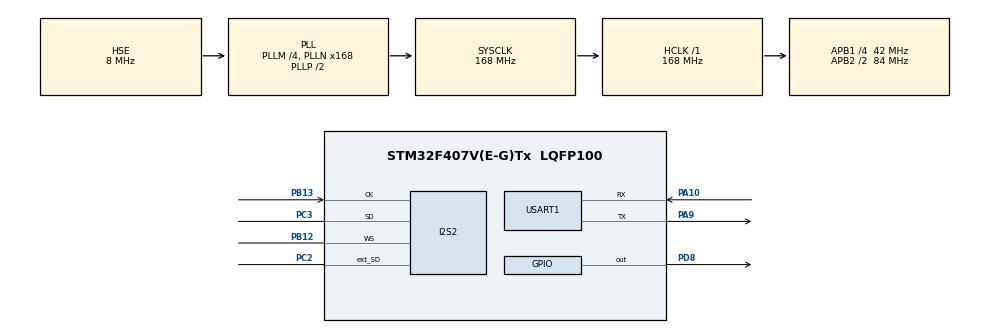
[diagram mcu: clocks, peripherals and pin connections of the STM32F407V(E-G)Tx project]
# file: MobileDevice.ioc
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Dma.I2S2_EXT_RX.0.Direction=DMA_PERIPH_TO_MEMORY
Dma.I2S2_EXT_RX.0.FIFOMode=DMA_FIFOMODE_DISABLE
Dma.I2S2_EXT_RX.0.Instance=DMA1_Stream3
Dma.I2S2_EXT_RX.0.MemDataAlignment=DMA_MDATAALIGN_HALFWORD
Dma.I2S2_EXT_RX.0.MemInc=DMA_MINC_ENABLE
Dma.I2S2_EXT_RX.0.Mode=DMA_CIRCULAR
Dma.I2S2_EXT_RX.0.PeriphDataAlignment=DMA_PDATAALIGN_HALFWORD
Dma.I2S2_EXT_RX.0.PeriphInc=DMA_PINC_DISABLE
Dma.I2S2_EXT_RX.0.Priority=DMA_PRIORITY_LOW
Dma.Request0=I2S2_EXT_RX
Dma.Request1=SPI2_TX
Dma.SPI2_TX.1.Direction=DMA_MEMORY_TO_PERIPH
Dma.SPI2_TX.1.FIFOMode=DMA_FIFOMODE_DISABLE
Dma.SPI2_TX.1.Instance=DMA1_Stream4
Dma.SPI2_TX.1.MemDataAlignment=DMA_MDATAALIGN_HALFWORD
Dma.SPI2_TX.1.MemInc=DMA_MINC_ENABLE
Dma.SPI2_TX.1.Mode=DMA_CIRCULAR
Dma.SPI2_TX.1.PeriphDataAlignment=DMA_PDATAALIGN_HALFWORD
Dma.SPI2_TX.1.PeriphInc=DMA_PINC_DISABLE
Dma.SPI2_TX.1.Priority=DMA_PRIORITY_LOW
I2S2.DataFormat=I2S_DATAFORMAT_16B_EXTENDED
I2S2.ErrorAudioFreq=-0.36 %
I2S2.FullDuplexMode=I2S_FULLDUPLEXMODE_ENABLE
I2S2.Instance=SPI$Index
I2S2.RealAudioFreq=7.971 KHz
I2S2.Standard=I2S_STANDARD_PCM_SHORT
I2S2.VirtualMode=I2S_MODE_SLAVE
Mcu.Family=STM32F4
Mcu.Name=STM32F407V(E-G)Tx
Mcu.Package=LQFP100
NVIC.DMA1_Stream3_IRQn=true\:0\:0\:false\:false\:true\:false
NVIC.DMA1_Stream4_IRQn=true\:0\:0\:false\:false\:true\:false
NVIC.PriorityGroup=NVIC_PRIORITYGROUP_4
NVIC.SPI2_IRQn=true\:0\:0\:false\:false\:true\:true
NVIC.USART1_IRQn=true\:0\:0\:false\:false\:true\:true
PA10.Mode=Asynchronous
PA10.Signal=USART1_RX
PA13.Mode=Serial_Wire
PA13.Signal=SYS_JTMS-SWDIO
PA14.Mode=Serial_Wire
PA14.Signal=SYS_JTCK-SWCLK
PA9.Mode=Asynchronous
PA9.Signal=USART1_TX
PB12.Mode=Full_Duplex_Slave
PB12.Signal=I2S2_WS
PB13.Mode=Full_Duplex_Slave
PB13.Signal=I2S2_CK
PC2.Mode=Full_Duplex_Slave
PC2.Signal=I2S2_ext_SD
PC3.Mode=Full_Duplex_Slave
PC3.Signal=I2S2_SD
PD8.Signal=GPIO_Output
PH0-OSC_IN.Mode=HSE-External-Oscillator
PH0-OSC_IN.Signal=RCC_OSC_IN
PH1-OSC_OUT.Mode=HSE-External-Oscillator
PH1-OSC_OUT.Signal=RCC_OSC_OUT
ProjectManager.HeapSize=0x200
ProjectManager.StackSize=0x400
ProjectManager.TargetToolchain=Other Toolchains (GPDSC)
RCC.48MHZClocksFreq_Value=84000000
RCC.AHBFreq_Value=168000000
RCC.APB1CLKDivider=RCC_HCLK_DIV4
RCC.APB1Freq_Value=42000000
RCC.APB1TimFreq_Value=84000000
RCC.APB2CLKDivider=RCC_HCLK_DIV2
RCC.APB2Freq_Value=84000000
RCC.APB2TimFreq_Value=168000000
RCC.CortexFreq_Value=168000000
RCC.HCLKFreq_Value=168000000
RCC.HSE_VALUE=8000000
RCC.HSI_VALUE=16000000
RCC.LSE_VALUE=32768
RCC.PLLI2SN=50
RCC.PLLM=4
RCC.PLLN=168
RCC.PLLSourceVirtual=RCC_PLLSOURCE_HSE
RCC.SYSCLKFreq_VALUE=168000000
RCC.SYSCLKSource=RCC_SYSCLKSOURCE_PLLCLK
RCC.VCOOutputFreq_Value=336000000
USART1.VirtualMode=VM_ASYNC
board=MobileDevice

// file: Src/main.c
/**
  ******************************************************************************
  * @file           : main.c
  * @brief          : Main program body
  ******************************************************************************
  ** This notice applies to any and all portions of this file
  * that are not between comment pairs USER CODE BEGIN and
  * USER CODE END. Other portions of this file, whether
  * inserted by the user or by software development tools
  * are owned by their respective copyright owners.
  *
  * COPYRIGHT(c) 2018 STMicroelectronics
  *
  * Redistribution and use in source and binary forms, with or without modification,
  * are permitted provided that the following conditions are met:
  *   1. Redistributions of source code must retain the above copyright notice,
  *      this list of conditions and the following disclaimer.
  *   2. Redistributions in binary form must reproduce the above copyright notice,
  *      this list of conditions and the following disclaimer in the documentation
  *      and/or other materials provided with the distribution.
  *   3. Neither the name of STMicroelectronics nor the names of its contributors
  *      may be used to endorse or promote products derived from this software
  *      without specific prior written permission.
  *
  * THIS SOFTWARE IS PROVIDED BY THE COPYRIGHT HOLDERS AND CONTRIBUTORS "AS IS"
  * AND ANY EXPRESS OR IMPLIED WARRANTIES, INCLUDING, BUT NOT LIMITED TO, THE
  * IMPLIED WARRANTIES OF MERCHANTABILITY AND FITNESS FOR A PARTICULAR PURPOSE ARE
  * DISCLAIMED. IN NO EVENT SHALL THE COPYRIGHT HOLDER OR CONTRIBUTORS BE LIABLE
  * FOR ANY DIRECT, INDIRECT, INCIDENTAL, SPECIAL, EXEMPLARY, OR CONSEQUENTIAL
  * DAMAGES (INCLUDING, BUT NOT LIMITED TO, PROCUREMENT OF SUBSTITUTE GOODS OR
  * SERVICES; LOSS OF USE, DATA, OR PROFITS; OR BUSINESS INTERRUPTION) HOWEVER
  * CAUSED AND ON ANY THEORY OF LIABILITY, WHETHER IN CONTRACT, STRICT LIABILITY,
  * OR TORT (INCLUDING NEGLIGENCE OR OTHERWISE) ARISING IN ANY WAY OUT OF THE USE
  * OF THIS SOFTWARE, EVEN IF ADVISED OF THE POSSIBILITY OF SUCH DAMAGE.
  *
  ******************************************************************************
  */
#include "main.h"
#include "stm32f4xx_hal.h"
#include "dma.h"
#include "i2s.h"
#include "usart.h"
#include "gpio.h"

/* USER CODE BEGIN Includes */
#include "string.h"
/* USER CODE END Includes */

/* USER CODE BEGIN PV */
/* Private variables ---------------------------------------------------------*/

/* USER CODE END PV */

void SystemClock_Config(void);

/* USER CODE BEGIN PFP */
/* Private function prototypes -----------------------------------------------*/

/* USER CODE END PFP */

/* USER CODE BEGIN 0 */

uint16_t rxTemp[128] = { 0 };
uint16_t txTemp[128] = { 0x5555,0x5555,0x5555,0x5555,0x5555,0x5555,0x5555,0x5555,0x5555,0x5555 };
uint8_t sendTemp[256] = { 0 };

/* USER CODE END 0 */

int main(void)
{

  /* MCU Configuration----------------------------------------------------------*/

  /* Reset of all peripherals, Initializes the Flash interface and the Systick. */
  HAL_Init();

  /* Configure the system clock */
  SystemClock_Config();

  /* Initialize all configured peripherals */
  MX_GPIO_Init();
  MX_DMA_Init();
  MX_USART1_UART_Init();
  MX_I2S2_Init();
  /* USER CODE BEGIN 2 */

  for (size_t i = 0; i < 128; i++)
  {
	  txTemp[i] = i;
  }

  /* USER CODE END 2 */

  /* Infinite loop */
  while (1)
  {

  /* USER CODE BEGIN 3 */
	  HAL_I2SEx_TransmitReceive_DMA(&hi2s2, txTemp, rxTemp, 128);
  }
  /* USER CODE END 3 */

}

void HAL_I2SEx_TxRxCpltCallback(I2S_HandleTypeDef *hi2s) {

	printf("hello\n");
	HAL_I2SEx_TransmitReceive_DMA(&hi2s2, txTemp, rxTemp, 128);
}

void SystemClock_Config(void)
{

  RCC_OscInitTypeDef RCC_OscInitStruct;
  RCC_ClkInitTypeDef RCC_ClkInitStruct;
  RCC_PeriphCLKInitTypeDef PeriphClkInitStruct;

    /**Configure the main internal regulator output voltage
    */
  __HAL_RCC_PWR_CLK_ENABLE();

  __HAL_PWR_VOLTAGESCALING_CONFIG(PWR_REGULATOR_VOLTAGE_SCALE1);

    /**Initializes the CPU, AHB and APB busses clocks
    */
  RCC_OscInitStruct.OscillatorType = RCC_OSCILLATORTYPE_HSE;
  RCC_OscInitStruct.HSEState = RCC_HSE_ON;
  RCC_OscInitStruct.PLL.PLLState = RCC_PLL_ON;
  RCC_OscInitStruct.PLL.PLLSource = RCC_PLLSOURCE_HSE;
  RCC_OscInitStruct.PLL.PLLM = 4;
  RCC_OscInitStruct.PLL.PLLN = 168;
  RCC_OscInitStruct.PLL.PLLP = RCC_PLLP_DIV2;
  RCC_OscInitStruct.PLL.PLLQ = 4;
  if (HAL_RCC_OscConfig(&RCC_OscInitStruct) != HAL_OK)
  {
    _Error_Handler(__FILE__, __LINE__);
  }

    /**Initializes the CPU, AHB and APB busses clocks
    */
  RCC_ClkInitStruct.ClockType = RCC_CLOCKTYPE_HCLK|RCC_CLOCKTYPE_SYSCLK
                              |RCC_CLOCKTYPE_PCLK1|RCC_CLOCKTYPE_PCLK2;
  RCC_ClkInitStruct.SYSCLKSource = RCC_SYSCLKSOURCE_PLLCLK;
  RCC_ClkInitStruct.AHBCLKDivider = RCC_SYSCLK_DIV1;
  RCC_ClkInitStruct.APB1CLKDivider = RCC_HCLK_DIV4;
  RCC_ClkInitStruct.APB2CLKDivider = RCC_HCLK_DIV2;

  if (HAL_RCC_ClockConfig(&RCC_ClkInitStruct, FLASH_LATENCY_5) != HAL_OK)
  {
    _Error_Handler(__FILE__, __LINE__);
  }

  PeriphClkInitStruct.PeriphClockSelection = RCC_PERIPHCLK_I2S;
  PeriphClkInitStruct.PLLI2S.PLLI2SN = 50;
  PeriphClkInitStruct.PLLI2S.PLLI2SR = 2;
  if (HAL_RCCEx_PeriphCLKConfig(&PeriphClkInitStruct) != HAL_OK)
  {
    _Error_Handler(__FILE__, __LINE__);
  }

    /**Configure the Systick interrupt time
    */
  HAL_SYSTICK_Config(HAL_RCC_GetHCLKFreq()/1000);

    /**Configure the Systick
    */
  HAL_SYSTICK_CLKSourceConfig(SYSTICK_CLKSOURCE_HCLK);

  /* SysTick_IRQn interrupt configuration */
  HAL_NVIC_SetPriority(SysTick_IRQn, 0, 0);
}

void _Error_Handler(char *file, int line)
{
  while(1)
  {
  }
}

/************************ (C) COPYRIGHT STMicroelectronics *****END OF FILE****/
